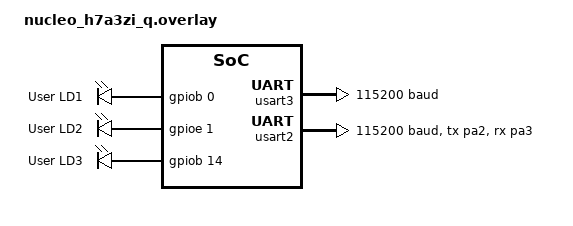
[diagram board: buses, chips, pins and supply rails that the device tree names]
// Device tree overlay for Nucleo H7A3ZI-Q board
// Increases available SRAM for F' application

// Delete the default small sram0 and redefine with more memory
/delete-node/ &sram0;

/ {
    soc {
        // Use full 1MB SRAM (AXI SRAM) to support 512KB heap + overhead
        // STM32H7A3ZI has 1MB AXI SRAM at 0x24000000
        sram0: memory@24000000 {
            compatible = "zephyr,memory-region", "mmio-sram";
            reg = <0x24000000 DT_SIZE_K(1024)>;
            zephyr,memory-region = "SRAM0";
        };
    };

    chosen {
        zephyr,sram = &sram0;
        /* Route Zephyr console/stdout to USART3 so POSIX stdio has a device */
        zephyr,console = &usart3;
        zephyr,stdout = &usart3;
        zephyr,stdin = &usart3;
    };

    aliases {
        led0 = &green_led;
    };
};

&leds {
    green_led: led_0 {
        gpios = <&gpiob 0 GPIO_ACTIVE_HIGH>;
        label = "User LD1";
    };
    
    yellow_led: led_1 {
        gpios = <&gpioe 1 GPIO_ACTIVE_HIGH>;
        label = "User LD2";
    };
    
    red_led: led_2 {
        gpios = <&gpiob 14 GPIO_ACTIVE_HIGH>;
        label = "User LD3";
    };
};

// Enable USART3 for console/debug on ST-Link Virtual COM port
&usart3 {
    status = "okay";
    current-speed = <115200>;
};

// Enable USART2 for F-Prime communication with RPi on PA2 (TX) and PA3 (RX)
// This matches the working uart_rpi_stm_test configuration
// PA2 = USART2_TX (connects to RPi GPIO15/RX)
// PA3 = USART2_RX (connects to RPi GPIO14/TX)
// Baud: 115200, Format: 8N1 (8 data bits, no parity, 1 stop bit)
&usart2 {
    status = "okay";
    current-speed = <115200>;
    pinctrl-0 = <&usart2_tx_pa2 &usart2_rx_pa3>;
    pinctrl-names = "default";
};

// Disable USB OTG to prevent conflicts with UART communication
&usbotg_hs {
    status = "disabled";
};
